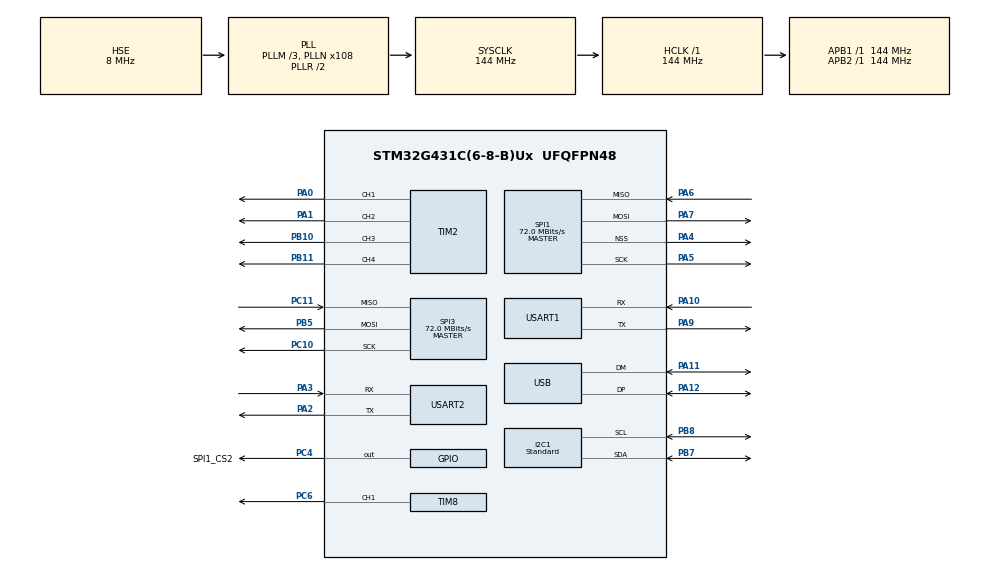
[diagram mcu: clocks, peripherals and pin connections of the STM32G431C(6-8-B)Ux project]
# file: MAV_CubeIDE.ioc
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FREERTOS.Tasks01=defaultTask,24,128,StartDefaultTask,Default,NULL,Dynamic,NULL,NULL
FREERTOS.configUSE_NEWLIB_REENTRANT=1
I2C1.I2C_Speed_Mode=I2C_Standard
I2C1.Timing=0x20B0D9FF
Mcu.Family=STM32G4
Mcu.Name=STM32G431C(6-8-B)Ux
Mcu.Package=UFQFPN48
NVIC.PriorityGroup=NVIC_PRIORITYGROUP_4
NVIC.TIM6_DAC_IRQn=true\:15\:0\:false\:false\:true\:false\:false\:true\:true
NVIC.TimeBase=TIM6_DAC_IRQn
NVIC.TimeBaseIP=TIM6
NVIC.USB_LP_IRQn=true\:5\:0\:false\:false\:true\:true\:false\:true\:true
PA0.Signal=S_TIM2_CH1
PA1.Signal=S_TIM2_CH2
PA10.GPIO_Speed=GPIO_SPEED_FREQ_VERY_HIGH
PA10.Mode=Asynchronous
PA10.Signal=USART1_RX
PA11.Mode=Device
PA11.Signal=USB_DM
PA12.Mode=Device
PA12.Signal=USB_DP
PA13.Mode=Serial_Wire
PA13.Signal=SYS_JTMS-SWDIO
PA14.Mode=Serial_Wire
PA14.Signal=SYS_JTCK-SWCLK
PA15.Signal=SPI3_NSS
PA2.GPIO_Speed=GPIO_SPEED_FREQ_VERY_HIGH
PA2.Mode=Asynchronous
PA2.Signal=USART2_TX
PA3.GPIO_Speed=GPIO_SPEED_FREQ_VERY_HIGH
PA3.Mode=Asynchronous
PA3.Signal=USART2_RX
PA4.GPIO_Speed=GPIO_SPEED_FREQ_LOW
PA4.Mode=NSS_Signal_Hard_Output
PA4.Signal=SPI1_NSS
PA5.GPIO_Speed=GPIO_SPEED_FREQ_VERY_HIGH
PA5.Mode=Full_Duplex_Master
PA5.Signal=SPI1_SCK
PA6.GPIO_Speed=GPIO_SPEED_FREQ_VERY_HIGH
PA6.Mode=Full_Duplex_Master
PA6.Signal=SPI1_MISO
PA7.GPIO_Speed=GPIO_SPEED_FREQ_VERY_HIGH
PA7.Mode=Full_Duplex_Master
PA7.Signal=SPI1_MOSI
PA9.GPIO_Speed=GPIO_SPEED_FREQ_VERY_HIGH
PA9.Mode=Asynchronous
PA9.Signal=USART1_TX
PB10.Signal=S_TIM2_CH3
PB11.Signal=S_TIM2_CH4
PB5.GPIO_Speed=GPIO_SPEED_FREQ_VERY_HIGH
PB5.Mode=Full_Duplex_Master
PB5.Signal=SPI3_MOSI
PB7.Mode=I2C
PB7.Signal=I2C1_SDA
PB8-BOOT0.Mode=I2C
PB8-BOOT0.Signal=I2C1_SCL
PC10.GPIO_Speed=GPIO_SPEED_FREQ_VERY_HIGH
PC10.Mode=Full_Duplex_Master
PC10.Signal=SPI3_SCK
PC11.GPIO_Speed=GPIO_SPEED_FREQ_VERY_HIGH
PC11.Mode=Full_Duplex_Master
PC11.Signal=SPI3_MISO
PC4.GPIO_Label=SPI1_CS2
PC4.Signal=GPIO_Output
PC6.Signal=S_TIM8_CH1
PF0-OSC_IN.Mode=HSE-External-Oscillator
PF0-OSC_IN.Signal=RCC_OSC_IN
PF1-OSC_OUT.Mode=HSE-External-Oscillator
PF1-OSC_OUT.Signal=RCC_OSC_OUT
ProjectManager.HeapSize=0x200
ProjectManager.StackSize=0x400
ProjectManager.TargetToolchain=STM32CubeIDE
RCC.ADC12Freq_Value=144000000
RCC.AHBFreq_Value=144000000
RCC.APB1Freq_Value=144000000
RCC.APB1TimFreq_Value=144000000
RCC.APB2Freq_Value=144000000
RCC.APB2TimFreq_Value=144000000
RCC.CortexFreq_Value=144000000
RCC.EXTERNAL_CLOCK_VALUE=12288000
RCC.HCLKFreq_Value=144000000
RCC.HSE_VALUE=8000000
RCC.HSI48_VALUE=48000000
RCC.HSI_VALUE=16000000
RCC.LSE_VALUE=32768
RCC.PLLM=RCC_PLLM_DIV3
RCC.PLLN=108
RCC.PLLQ=RCC_PLLQ_DIV6
RCC.PLLSourceVirtual=RCC_PLLSOURCE_HSE
RCC.SYSCLKFreq_VALUE=144000000
RCC.SYSCLKSource=RCC_SYSCLKSOURCE_PLLCLK
RCC.USBFreq_Value=48000000
RCC.VCOOutputFreq_Value=288000000
SH.S_TIM2_CH1.0=TIM2_CH1,PWM Generation1 CH1
SH.S_TIM2_CH2.0=TIM2_CH2,PWM Generation2 CH2
SH.S_TIM2_CH3.0=TIM2_CH3,PWM Generation3 CH3
SH.S_TIM2_CH4.0=TIM2_CH4,PWM Generation4 CH4
SH.S_TIM8_CH1.0=TIM8_CH1,PWM Generation1 CH1
SPI1.BaudRatePrescaler=SPI_BAUDRATEPRESCALER_2
SPI1.CalculateBaudRate=72.0 MBits/s
SPI1.Direction=SPI_DIRECTION_2LINES
SPI1.Mode=SPI_MODE_MASTER
SPI1.VirtualNSS=VM_NSSHARD
SPI1.VirtualType=VM_MASTER
SPI3.CalculateBaudRate=72.0 MBits/s
SPI3.Direction=SPI_DIRECTION_2LINES
SPI3.Mode=SPI_MODE_MASTER
SPI3.VirtualType=VM_MASTER
TIM2.Channel-PWM\ Generation1\ CH1=TIM_CHANNEL_1
TIM2.Channel-PWM\ Generation2\ CH2=TIM_CHANNEL_2
TIM2.Channel-PWM\ Generation3\ CH3=TIM_CHANNEL_3
TIM2.Channel-PWM\ Generation4\ CH4=TIM_CHANNEL_4
TIM8.Channel-PWM\ Generation1\ CH1=TIM_CHANNEL_1
USART1.VirtualMode-Asynchronous=VM_ASYNC
USART2.VirtualMode-Asynchronous=VM_ASYNC
USB_DEVICE.CLASS_NAME_FS=CDC
USB_DEVICE.VirtualMode=Cdc
USB_DEVICE.VirtualModeFS=Cdc_FS
VP_CRC_VS_CRC.Mode=CRC_Activate
VP_FREERTOS_VS_CMSIS_V2.Mode=CMSIS_V2
VP_SYS_VS_DBSignals.Mode=DisableDeadBatterySignals
VP_SYS_VS_tim6.Mode=TIM6
VP_TIM2_VS_ClockSourceINT.Mode=Internal
VP_USB_DEVICE_VS_USB_DEVICE_CDC_FS.Mode=CDC_FS
board=custom

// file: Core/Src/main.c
/* USER CODE BEGIN Header */
/**
  ******************************************************************************
  * @file           : main.c
  * @brief          : Main program body
  ******************************************************************************
  * @attention
  *
  * Copyright (c) 2024 STMicroelectronics.
  * All rights reserved.
  *
  * This software is licensed under terms that can be found in the LICENSE file
  * in the root directory of this software component.
  * If no LICENSE file comes with this software, it is provided AS-IS.
  *
  ******************************************************************************
  */
/* USER CODE END Header */
#include "main.h"
#include "cmsis_os.h"
#include "crc.h"
#include "i2c.h"
#include "spi.h"
#include "tim.h"
#include "usart.h"
#include "usb_device.h"
#include "gpio.h"

/* USER CODE BEGIN PM */
#define USE_MICROLIB 0  // 如果不使用微库，请将其置0!!!
/* USER CODE END PM */

void SystemClock_Config(void);
void MX_FREERTOS_Init(void);
/* USER CODE BEGIN PFP */
void MX_FREERTOS_Init(void);
/* USER CODE END PFP */

/* USER CODE BEGIN 0 */
#if !USE_MICROLIB
  __asm(".global __use_no_semihosting\n\t");  // 关闭半主机模�?
//		struct __FILE {
//		int handle;
//		};
//		std::FILE __stdout;
  void _sys_exit(int x) {
    x = x;
  }

	// 若报�?: __use_no_semihosting was requested, but _ttywrch was referenced, 增加如下函数
  void _ttywrch(int ch) {
	ch = ch;
  }

  char *_sys_command_string(char *cmd, int len) {
	return 0;
  }
#endif
/* USER CODE END 0 */

int main(void)
{

  /* MCU Configuration--------------------------------------------------------*/

  /* Reset of all peripherals, Initializes the Flash interface and the Systick. */
  HAL_Init();

  /* Configure the system clock */
  SystemClock_Config();

  /* Initialize all configured peripherals */
  MX_GPIO_Init();
  MX_CRC_Init();
  MX_SPI1_Init();
  MX_SPI3_Init();
  MX_USART1_UART_Init();
  MX_USART2_UART_Init();
  MX_TIM2_Init();
  MX_TIM8_Init();
  MX_I2C1_Init();

  /* Init scheduler */
  osKernelInitialize();

  /* Call init function for freertos objects (in cmsis_os2.c) */
  MX_FREERTOS_Init();

  /* Start scheduler */
  osKernelStart();

  /* We should never get here as control is now taken by the scheduler */

  /* Infinite loop */
  while (1) {

  }
}

void SystemClock_Config(void)
{
  RCC_OscInitTypeDef RCC_OscInitStruct = {0};
  RCC_ClkInitTypeDef RCC_ClkInitStruct = {0};

  /** Configure the main internal regulator output voltage
  */
  HAL_PWREx_ControlVoltageScaling(PWR_REGULATOR_VOLTAGE_SCALE1);

  /** Initializes the RCC Oscillators according to the specified parameters
  * in the RCC_OscInitTypeDef structure.
  */
  RCC_OscInitStruct.OscillatorType = RCC_OSCILLATORTYPE_HSE;
  RCC_OscInitStruct.HSEState = RCC_HSE_ON;
  RCC_OscInitStruct.PLL.PLLState = RCC_PLL_ON;
  RCC_OscInitStruct.PLL.PLLSource = RCC_PLLSOURCE_HSE;
  RCC_OscInitStruct.PLL.PLLM = RCC_PLLM_DIV3;
  RCC_OscInitStruct.PLL.PLLN = 108;
  RCC_OscInitStruct.PLL.PLLP = RCC_PLLP_DIV2;
  RCC_OscInitStruct.PLL.PLLQ = RCC_PLLQ_DIV6;
  RCC_OscInitStruct.PLL.PLLR = RCC_PLLR_DIV2;
  if (HAL_RCC_OscConfig(&RCC_OscInitStruct) != HAL_OK)
  {
    Error_Handler();
  }

  /** Initializes the CPU, AHB and APB buses clocks
  */
  RCC_ClkInitStruct.ClockType = RCC_CLOCKTYPE_HCLK|RCC_CLOCKTYPE_SYSCLK
                              |RCC_CLOCKTYPE_PCLK1|RCC_CLOCKTYPE_PCLK2;
  RCC_ClkInitStruct.SYSCLKSource = RCC_SYSCLKSOURCE_PLLCLK;
  RCC_ClkInitStruct.AHBCLKDivider = RCC_SYSCLK_DIV1;
  RCC_ClkInitStruct.APB1CLKDivider = RCC_HCLK_DIV1;
  RCC_ClkInitStruct.APB2CLKDivider = RCC_HCLK_DIV1;

  if (HAL_RCC_ClockConfig(&RCC_ClkInitStruct, FLASH_LATENCY_4) != HAL_OK)
  {
    Error_Handler();
  }
}

void HAL_TIM_PeriodElapsedCallback(TIM_HandleTypeDef *htim)
{
  if (htim->Instance == TIM6) {
    HAL_IncTick();
  }
}

void Error_Handler(void)
{
  __disable_irq();
  while (1)
  {
  }
}
